# ATSAM4E16C register map
Vendor: Atmel; Series: SAM4E; File version: 0
CPU: CM4 r0p0, selectable endian, no MPU, FPU, 4 interrupt priority bits
Registers are 32-bit, read-write, reset 0x0 unless marked. A register's access mark holds for its fields unless they carry their own. Offsets are from the block's base; [hi:lo] are bit positions; {n}, {i} and the like mark numbered series; 'fields as' and 'values as' point back to an identical list.

## AFEC0 — Analog-Front-End Controller 0
Base 0x400B0000; register names take the prefix AFEC0_
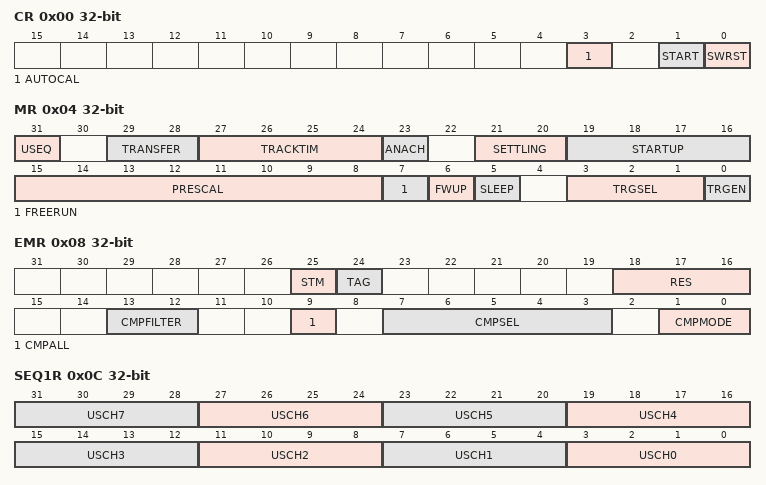
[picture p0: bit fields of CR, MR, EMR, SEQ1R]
0x00 CR wo reset not defined — Control Register
  [3] AUTOCAL — Automatic Calibration of AFE
  [1] START — Start Conversion
  [0] SWRST — Software Reset
0x04 MR — Mode Register
  [31] USEQ — Use Sequence Enable
    0=NUM_ORDER (Normal Mode: The controller converts channels in a simple numeric order.); 1=REG_ORDER (User Sequence Mode: The sequence respects what is defined in AFE_SEQR1 and AFE_SEQR2 registers.)
  [29:28] TRANSFER — Transfer Period
  [27:24] TRACKTIM — Tracking Time
  [23] ANACH — Analog Change
    0=NONE (No analog change on channel switching: DIFF0, GAIN0 and OFF0 are used for all channels); 1=ALLOWED (Allows different analog settings for each channel. See AFE_CGR and AFE_CDOR Registers)
  [21:20] SETTLING — Analog Settling Time
    0=AST3 (3 periods of AFEClock); 1=AST5 (5 periods of AFEClock); 2=AST9 (9 periods of AFEClock); 3=AST17 (17 periods of AFEClock)
  [19:16] STARTUP — Start Up Time
    0=SUT0 (0 periods of AFEClock); 1=SUT8 (8 periods of AFEClock); 2=SUT16 (16 periods of AFEClock); 3=SUT24 (24 periods of AFEClock); 4=SUT64 (64 periods of AFEClock); 5=SUT80 (80 periods of AFEClock); 6=SUT96 (96 periods of AFEClock); 7=SUT112 (112 periods of AFEClock); 8=SUT512 (512 periods of AFEClock); 9=SUT576 (576 periods of AFEClock); 10=SUT640 (640 periods of AFEClock); 11=SUT704 (704 periods of AFEClock); 12=SUT768 (768 periods of AFEClock); 13=SUT832 (832 periods of AFEClock); 14=SUT896 (896 periods of AFEClock); 15=SUT960 (960 periods of AFEClock)
  [15:8] PRESCAL — Prescaler Rate Selection
  [7] FREERUN — Free Run Mode
    0=OFF (Normal Mode); 1=ON (Free Run Mode: Never wait for any trigger.)
  [6] FWUP — Fast Wake Up
    0=OFF (Normal Sleep Mode: The sleep mode is defined by the SLEEP bit); 1=ON (Fast Wake Up Sleep Mode: The Voltage reference is ON between conversions and AFE Core is OFF)
  [5] SLEEP — Sleep Mode
    0=NORMAL (Normal Mode: The AFE Core and reference voltage circuitry are kept ON between conversions); 1=SLEEP (Sleep Mode: The AFE Core and reference voltage circuitry are OFF between conversions)
  [3:1] TRGSEL — Trigger Selection
    0=AFE_TRIG0 (ADTRG pin); 1=AFE_TRIG1 (TIO Output of the Timer Counter Channel 0); 2=AFE_TRIG2 (TIO Output of the Timer Counter Channel 1); 3=AFE_TRIG3 (TIO Output of the Timer Counter Channel 2); 4=AFE_TRIG4 (PWM Event Line 0); 5=AFE_TRIG5 (PWM Event Line 1)
  [0] TRGEN — Trigger Enable
    0=DIS (Hardware triggers are disabled. Starting a conversion is only possible by software.); 1=EN (Hardware trigger selected by TRGSEL field is enabled.)
0x08 EMR — Extended Mode Register
  [25] STM — Single Trigger Mode
  [24] TAG — TAG of AFE_LDCR register
  [18:16] RES — Resolution
    0=NO_AVERAGE (12-bit resolution, AFE sample rate is maximum (no averaging).); 1=LOW_RES (10-bit resolution, AFE sample rate is maximum (no averaging).); 2=OSR4 (13-bit resolution, AFE sample rate divided by 4 (averaging).); 3=OSR16 (14-bit resolution, AFE sample rate divided by 16 (averaging).); 4=OSR64 (15-bit resolution, AFE sample rate divided by 64 (averaging).); 5=OSR256 (16-bit resolution, AFE sample rate divided by 256 (averaging).)
  [13:12] CMPFILTER — Compare Event Filtering
  [9] CMPALL — Compare All Channels
  [7:3] CMPSEL — Comparison Selected Channel
  [1:0] CMPMODE — Comparison Mode
    0=LOW (Generates an event when the converted data is lower than the low threshold of the window.); 1=HIGH (Generates an event when the converted data is higher than the high threshold of the window.); 2=IN (Generates an event when the converted data is in the comparison window.); 3=OUT (Generates an event when the converted data is out of the comparison window.)
0x0C SEQ1R — Channel Sequence 1 Register
  [4n+3:4n] USCH{n} (n=0..7) — User Sequence Number {n}
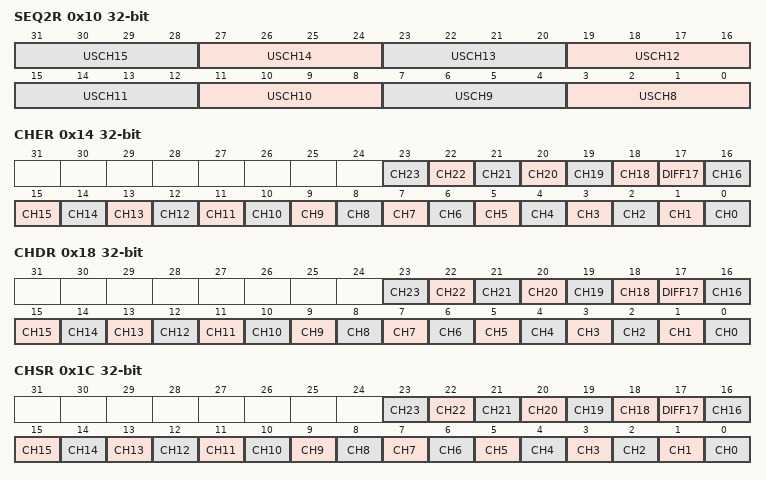
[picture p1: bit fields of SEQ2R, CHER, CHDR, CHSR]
0x10 SEQ2R — Channel Sequence 2 Register
  [4n-29:4n-32] USCH{n} (n=8..15) — User Sequence Number {n}
0x14 CHER wo reset not defined — Channel Enable Register
  [n] CH{n} (n=18..23) — Channel {n} Enable
  [17] DIFF17
  [n] CH{n} (n=0..16) — Channel {n} Enable
0x18 CHDR wo reset not defined — Channel Disable Register
  [n] CH{n} (n=18..23) — Channel {n} Disable
  [17] DIFF17
  [n] CH{n} (n=0..16) — Channel {n} Disable
0x1C CHSR ro — Channel Status Register
  [n] CH{n} (n=18..23) — Channel {n} Status
  [17] DIFF17
  [n] CH{n} (n=0..16) — Channel {n} Status
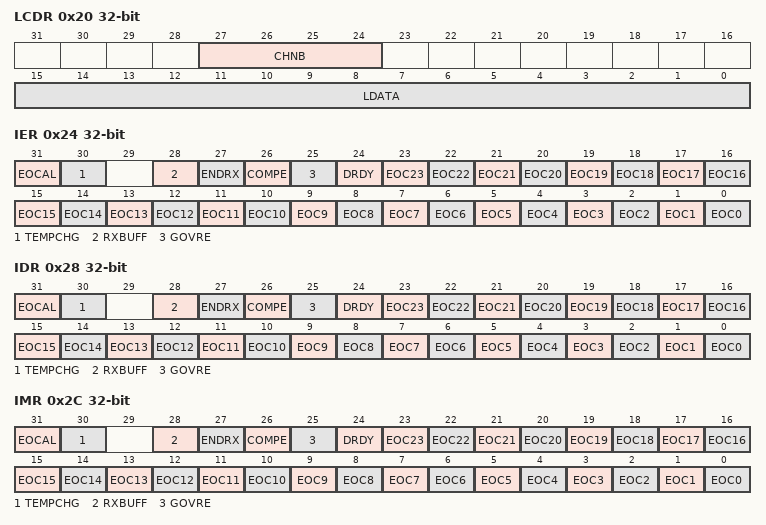
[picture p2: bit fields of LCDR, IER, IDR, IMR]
0x20 LCDR ro — Last Converted Data Register
  [27:24] CHNB — Channel Number
  [15:0] LDATA — Last Data Converted
0x24 IER wo reset not defined — Interrupt Enable Register
  [31] EOCAL — End of Calibration Sequence Interrupt Enable
  [30] TEMPCHG — Temperature Change Interrupt Enable
  [28] RXBUFF — Receive Buffer Full Interrupt Enable
  [27] ENDRX — End of Receive Buffer Interrupt Enable
  [26] COMPE — Comparison Event Interrupt Enable+
  [25] GOVRE — General Overrun Error Interrupt Enable
  [24] DRDY — Data Ready Interrupt Enable
  [n] EOC{n} (n=0..23) — End of Conversion Interrupt Enable {n}
0x28 IDR wo reset not defined — Interrupt Disable Register
  [31] EOCAL — End of Calibration Sequence Interrupt Disable
  [30] TEMPCHG — Temperature Change Interrupt Disable
  [28] RXBUFF — Receive Buffer Full Interrupt Disable
  [27] ENDRX — End of Receive Buffer Interrupt Disable
  [26] COMPE — Comparison Event Interrupt Disable
  [25] GOVRE — General Overrun Error Interrupt Disable
  [24] DRDY — Data Ready Interrupt Disable
  [n] EOC{n} (n=0..23) — End of Conversion Interrupt Disable {n}
0x2C IMR ro — Interrupt Mask Register
  [31] EOCAL — End of Calibration Sequence Interrupt Mask
  [30] TEMPCHG — Temperature Change Interrupt Mask
  [28] RXBUFF — Receive Buffer Full Interrupt Mask
  [27] ENDRX — End of Receive Buffer Interrupt Mask
  [26] COMPE — Comparison Event Interrupt Mask
  [25] GOVRE — General Overrun Error Interrupt Mask
  [24] DRDY — Data Ready Interrupt Mask
  [n] EOC{n} (n=0..23) — End of Conversion Interrupt Mask {n}
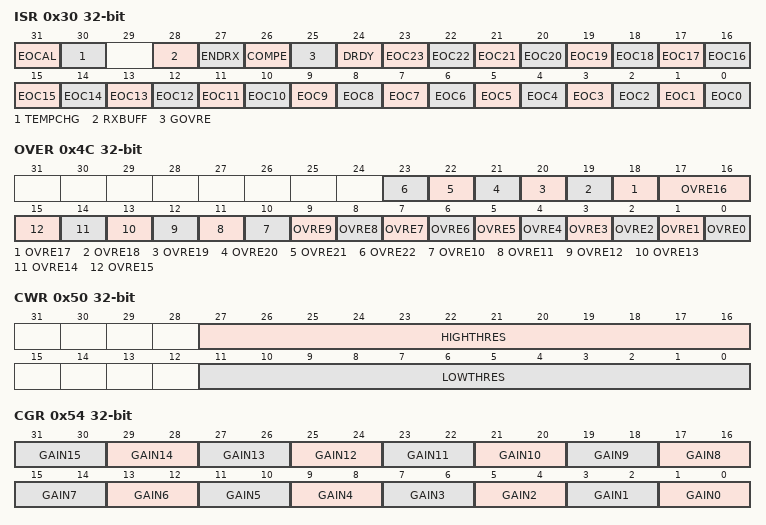
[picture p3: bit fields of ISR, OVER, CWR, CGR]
0x30 ISR ro — Interrupt Status Register
  [31] EOCAL — End of Calibration Sequence
  [30] TEMPCHG — Temperature Change
  [28] RXBUFF — RX Buffer Full
  [27] ENDRX — End of RX Buffer
  [26] COMPE — Comparison Error
  [25] GOVRE — General Overrun Error
  [24] DRDY — Data Ready
  [n] EOC{n} (n=0..23) — End of Conversion {n}
0x4C OVER ro — Overrun Status Register
  [n+1] OVRE{n} (n=17..22) — Overrun Error {n}
  [17:16] OVRE16 — Overrun Error 16
  [n] OVRE{n} (n=0..15) — Overrun Error {n}
0x50 CWR — Compare Window Register
  [27:16] HIGHTHRES — High Threshold
  [11:0] LOWTHRES — Low Threshold
0x54 CGR — Channel Gain Register
  [2n+1:2n] GAIN{n} (n=0..15) — Gain for channel {n}
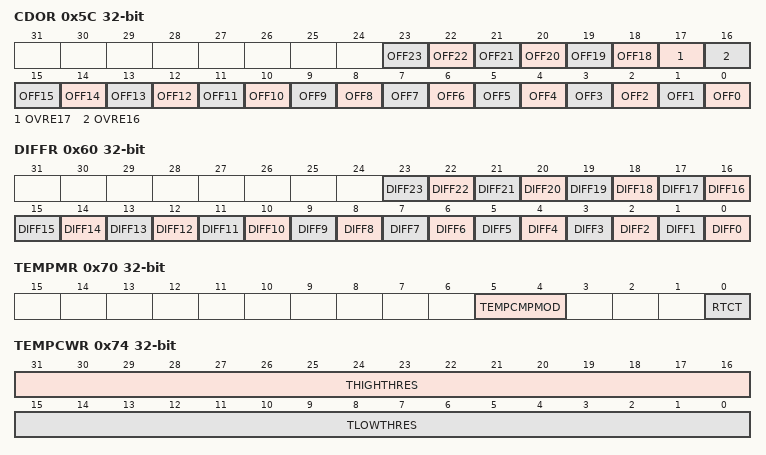
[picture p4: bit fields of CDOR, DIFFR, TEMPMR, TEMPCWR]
0x5C CDOR — Channel DC Offset Register
  [n] OFF{n} (n=18..23) — Offset for channel {n}
  [17] OVRE17
  [16] OVRE16
  [n] OFF{n} (n=0..15) — Offset for channel {n}
0x60 DIFFR — Channel Differential Register
  [n] DIFF{n} (n=0..23) — Differential inputs for channel {n}
0x64 CSELR ro — Channel Register Selection
  [3:0] CSEL — Channel Selection
0x68 CDR ro — Channel Data Register
  [11:0] DATA — Converted Data
0x6C COCR ro — Channel Offset Compensation Register
  [11:0] AOFF — Analog Offset
0x70 TEMPMR — Temperature Sensor Mode Register
  [5:4] TEMPCMPMOD — Temperature Comparison Mode
    values as EMR.CMPMODE
  [0] RTCT — Temperature Sensor RTC Trigger mode
0x74 TEMPCWR — Temperature Compare Window Register
  [31:16] THIGHTHRES — Temperature High Threshold
  [15:0] TLOWTHRES — Temperature Low Threshold
0x94 ACR reset 0x100 — Analog Control Register
  [9:8] IBCTL — AFE Bias Current Control
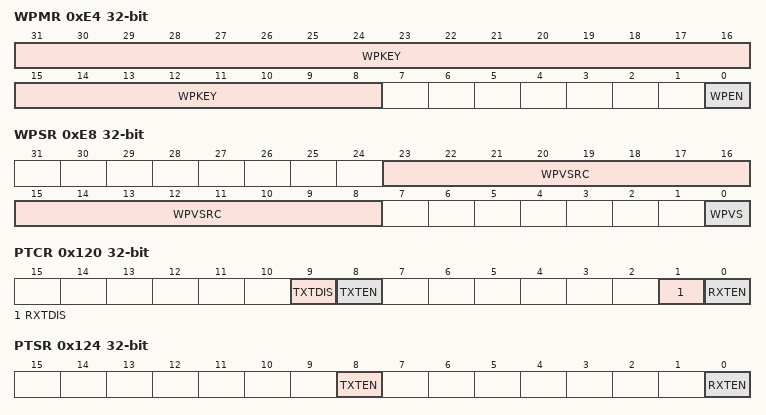
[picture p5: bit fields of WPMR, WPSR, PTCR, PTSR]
0xE4 WPMR — Write Protect Mode Register
  [31:8] WPKEY — Write Protect KEY
  [0] WPEN — Write Protect Enable
0xE8 WPSR ro — Write Protect Status Register
  [23:8] WPVSRC — Write Protect Violation Source
  [0] WPVS — Write Protect Violation Status
0x100 RPR — Receive Pointer Register
  [31:0] RXPTR
0x104 RCR — Receive Counter Register
  [15:0] RXCTR
0x110 RNPR — Receive Next Pointer Register
  [31:0] RXNPTR — Receive Next Pointer
0x114 RNCR — Receive Next Counter Register
  [15:0] RXNCTR — Receive Next Counter
0x120 PTCR wo — Transfer Control Register
  [9] TXTDIS — Transmitter Transfer Disable
  [8] TXTEN — Transmitter Transfer Enable
  [1] RXTDIS — Receiver Transfer Disable
  [0] RXTEN — Receiver Transfer Enable
0x124 PTSR ro — Transfer Status Register
  [8] TXTEN — Transmitter Transfer Enable
  [0] RXTEN — Receiver Transfer Enable

## AFEC1 — Analog-Front-End Controller 1
Base 0x400B4000; register names take the prefix AFEC1_
Registers as AFEC0.

## Notices in the file
SAM Software Package License
Copyright (c) %copyright_year%, Atmel Corporation
All rights reserved.
Redistribution and use in source and binary forms, with or without
modification, are permitted provided that the following condition is met:
- Redistributions of source code must retain the above copyright notice,
this list of conditions and the disclaimer below.
Atmel's name may not be used to endorse or promote products derived from
this software without specific prior written permission.
DISCLAIMER:  THIS SOFTWARE IS PROVIDED BY ATMEL "AS IS" AND ANY EXPRESS OR
IMPLIED WARRANTIES, INCLUDING, BUT NOT LIMITED TO, THE IMPLIED WARRANTIES OF
MERCHANTABILITY, FITNESS FOR A PARTICULAR PURPOSE AND NON-INFRINGEMENT ARE
DISCLAIMED. IN NO EVENT SHALL ATMEL BE LIABLE FOR ANY DIRECT, INDIRECT,
INCIDENTAL, SPECIAL, EXEMPLARY, OR CONSEQUENTIAL DAMAGES (INCLUDING, BUT NOT
LIMITED TO, PROCUREMENT OF SUBSTITUTE GOODS OR SERVICES; LOSS OF USE, DATA,
OR PROFITS; OR BUSINESS INTERRUPTION) HOWEVER CAUSED AND ON ANY THEORY OF
LIABILITY, WHETHER IN CONTRACT, STRICT LIABILITY, OR TORT (INCLUDING
NEGLIGENCE OR OTHERWISE) ARISING IN ANY WAY OUT OF THE USE OF THIS SOFTWARE,
EVEN IF ADVISED OF THE POSSIBILITY OF SUCH DAMAGE.
